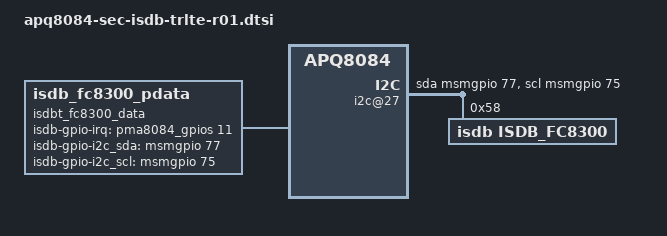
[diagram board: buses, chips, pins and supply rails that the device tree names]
/* Copyright (c) 2012-2014, The Linux Foundation. All rights reserved.
 *
 * This program is free software; you can redistribute it and/or modify
 * it under the terms of the GNU General Public License version 2 and
 * only version 2 as published by the Free Software Foundation.
 *
 * This program is distributed in the hope that it will be useful,
 * but WITHOUT ANY WARRANTY; without even the implied warranty of
 * MERCHANTABILITY or FITNESS FOR A PARTICULAR PURPOSE.  See the
 * GNU General Public License for more details.
 */

&soc {
	tspp: msm_tspp@f99d8000 {
		status = "okay";
	};

	i2c@27 
	{
		cell-index = <27>;
		compatible = "i2c-gpio";
		gpios = <&msmgpio 77 0 /* sda */
				&msmgpio 75 0 /* scl */
		>;
		i2c-gpio,delay-us = <2>;
		#address-cells = <1>;
		#size-cells = <0>;
		
		isdb_fc8300@58 {
			compatible = "isdb,isdb_fc8300";
			reg = <0x58>;
		};
  	};

	isdbt_fc8300_data {
		compatible = "isdb_fc8300_pdata";
		qcom,isdb-gpio-pwr-en = <305>;
		qcom,isdb-gpio-rst = <315>;
		qcom,isdb-gpio-irq = <&pma8084_gpios 11 0>;
		qcom,isdb-gpio-i2c_sda = <&msmgpio 77 0>;
		qcom,isdb-gpio-i2c_scl = <&msmgpio 75 0>;
		qcom,isdb-bbm-xtal-freq = <26000>;
	};

};
